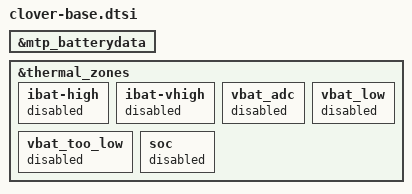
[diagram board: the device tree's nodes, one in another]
#include "dsi-panel-nt51021-boe-10wu-video.dtsi"
#include "dsi-panel-nt51021-boe-video.dtsi"
#include "clover-overlay.dtsi"

&mtp_batterydata {
	#include "batterydata-zql5018-6000mah.dtsi"
	#include "batterydata-zql6019-8600mah.dtsi"
};

&thermal_zones {
	ibat-high {
		status = "disabled";
	};
	ibat-vhigh {
		status = "disabled";
	};
	vbat_adc {
		status = "disabled";
	};
	vbat_low {
		status = "disabled";
	};
	vbat_too_low {
		status = "disabled";
        };
        soc  {
                status = "disabled";
	};
};

